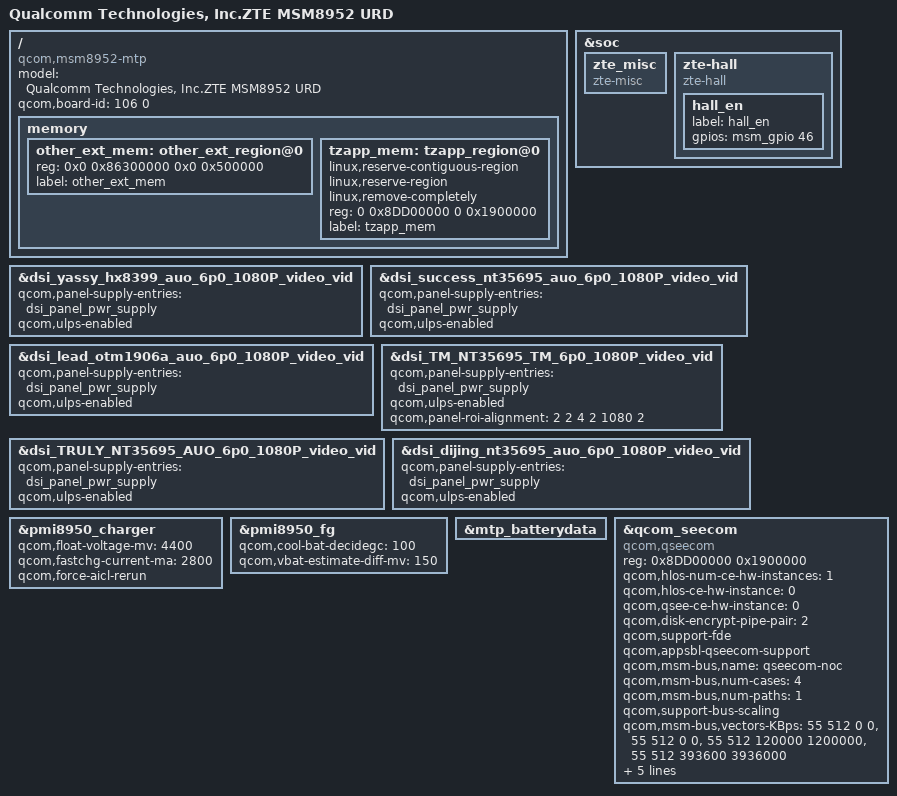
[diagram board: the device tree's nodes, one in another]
/*
 * Copyright (c) 2015, The Linux Foundation. All rights reserved.
 *
 * This program is free software; you can redistribute it and/or modify
 * it under the terms of the GNU General Public License version 2 and
 * only version 2 as published by the Free Software Foundation.
 *
 * This program is distributed in the hope that it will be useful,
 * but WITHOUT ANY WARRANTY; without even the implied warranty of
 * MERCHANTABILITY or FITNESS FOR A PARTICULAR PURPOSE.  See the
 * GNU General Public License for more details.
 */

/dts-v1/;

#include "msm8952-mtp.dtsi"
#include "zte-msm8952-urd.dtsi"

#include "dsi-panel-zte-success-nt35695-auo-6p0-1080p-cmd.dtsi"
#include "dsi-panel-zte-tm-nt35695-tm-6p0-1080p-video.dtsi"
#include "dsi-panel-zte-YASSY-HX8399-auo-6p0-1080p-video.dtsi"
#include "dsi-panel-zte-lead_otm1906a_auo_6p0_1080p_cmd.dtsi"
#include "dsi-panel-zte-truly-nt35695-auo-6p0-1080p-video.dtsi"
#include "dsi-panel-zte-dijing-nt35695-auo-6p0-1080p-video.dtsi"

/ {
	model = "Qualcomm Technologies, Inc.ZTE MSM8952 URD";
	compatible = "qcom,msm8952-mtp", "qcom,msm8952", "qcom,mtp";
	qcom,board-id= <106 0>;

	memory {
		#address-cells = <2>;
		#size-cells = <2>;

            other_ext_mem: other_ext_region@0 {
			reg = <0x0 0x86300000 0x0 0x500000>;
			label = "other_ext_mem";
		};

            tzapp_mem: tzapp_region@0 {
                  linux,reserve-contiguous-region;
                  linux,reserve-region;
                  linux,remove-completely;
                  reg = <0 0x8DD00000 0 0x1900000>;
                  label = "tzapp_mem";
            };
	};
};
&soc {
        zte_misc {
                compatible = "zte-misc";
        };
        zte-hall {
                compatible = "zte-hall";
                hall_en{
                        label = "hall_en";
                        gpios = <&msm_gpio 46 0x0>;
		};
        };
};
&dsi_yassy_hx8399_auo_6p0_1080P_video_vid {
	qcom,panel-supply-entries = <&dsi_panel_pwr_supply>;
	qcom,ulps-enabled;
};
&dsi_success_nt35695_auo_6p0_1080P_video_vid {
	qcom,panel-supply-entries = <&dsi_panel_pwr_supply>;
	qcom,ulps-enabled;
};
&dsi_lead_otm1906a_auo_6p0_1080P_video_vid {
	qcom,panel-supply-entries = <&dsi_panel_pwr_supply>;
	qcom,ulps-enabled;
};
&dsi_TM_NT35695_TM_6p0_1080P_video_vid {
	qcom,panel-supply-entries = <&dsi_panel_pwr_supply>;
	qcom,ulps-enabled;
	qcom,panel-roi-alignment = <2 2 4 2 1080 2>;
};
&dsi_TRULY_NT35695_AUO_6p0_1080P_video_vid {
	qcom,panel-supply-entries = <&dsi_panel_pwr_supply>;
	qcom,ulps-enabled;
};
&dsi_dijing_nt35695_auo_6p0_1080P_video_vid {
	qcom,panel-supply-entries = <&dsi_panel_pwr_supply>;
	qcom,ulps-enabled;
};
&pmi8950_charger {
	qcom,float-voltage-mv = <4400>;
	qcom,fastchg-current-ma = <2800>;
	qcom,force-aicl-rerun;
};
&pmi8950_fg{
	qcom,cool-bat-decidegc = <100>;
	qcom,vbat-estimate-diff-mv = <150>;
};
&mtp_batterydata {
		#include "ZTE_P895A16_3400mAh.dtsi"
};
&qcom_seecom{
		compatible = "qcom,qseecom";
		reg = <0x8DD00000 0x1900000>;
		reg-names = "secapp-region";
		qcom,hlos-num-ce-hw-instances = <1>;
		qcom,hlos-ce-hw-instance = <0>;
		qcom,qsee-ce-hw-instance = <0>;
		qcom,disk-encrypt-pipe-pair = <2>;
		qcom,support-fde;
		qcom,appsbl-qseecom-support;
		qcom,msm-bus,name = "qseecom-noc";
		qcom,msm-bus,num-cases = <4>;
		qcom,msm-bus,num-paths = <1>;
		qcom,support-bus-scaling;
		qcom,msm-bus,vectors-KBps =
			<55 512 0 0>,
			<55 512 0 0>,
			<55 512 120000 1200000>,
			<55 512 393600 3936000>;
		clocks = <&clock_gcc clk_crypto_clk_src>,
			 <&clock_gcc clk_gcc_crypto_clk>,
			 <&clock_gcc clk_gcc_crypto_ahb_clk>,
			 <&clock_gcc clk_gcc_crypto_axi_clk>;
		clock-names = "core_clk_src", "core_clk",
				"iface_clk", "bus_clk";
		qcom,ce-opp-freq = <100000000>;
};
